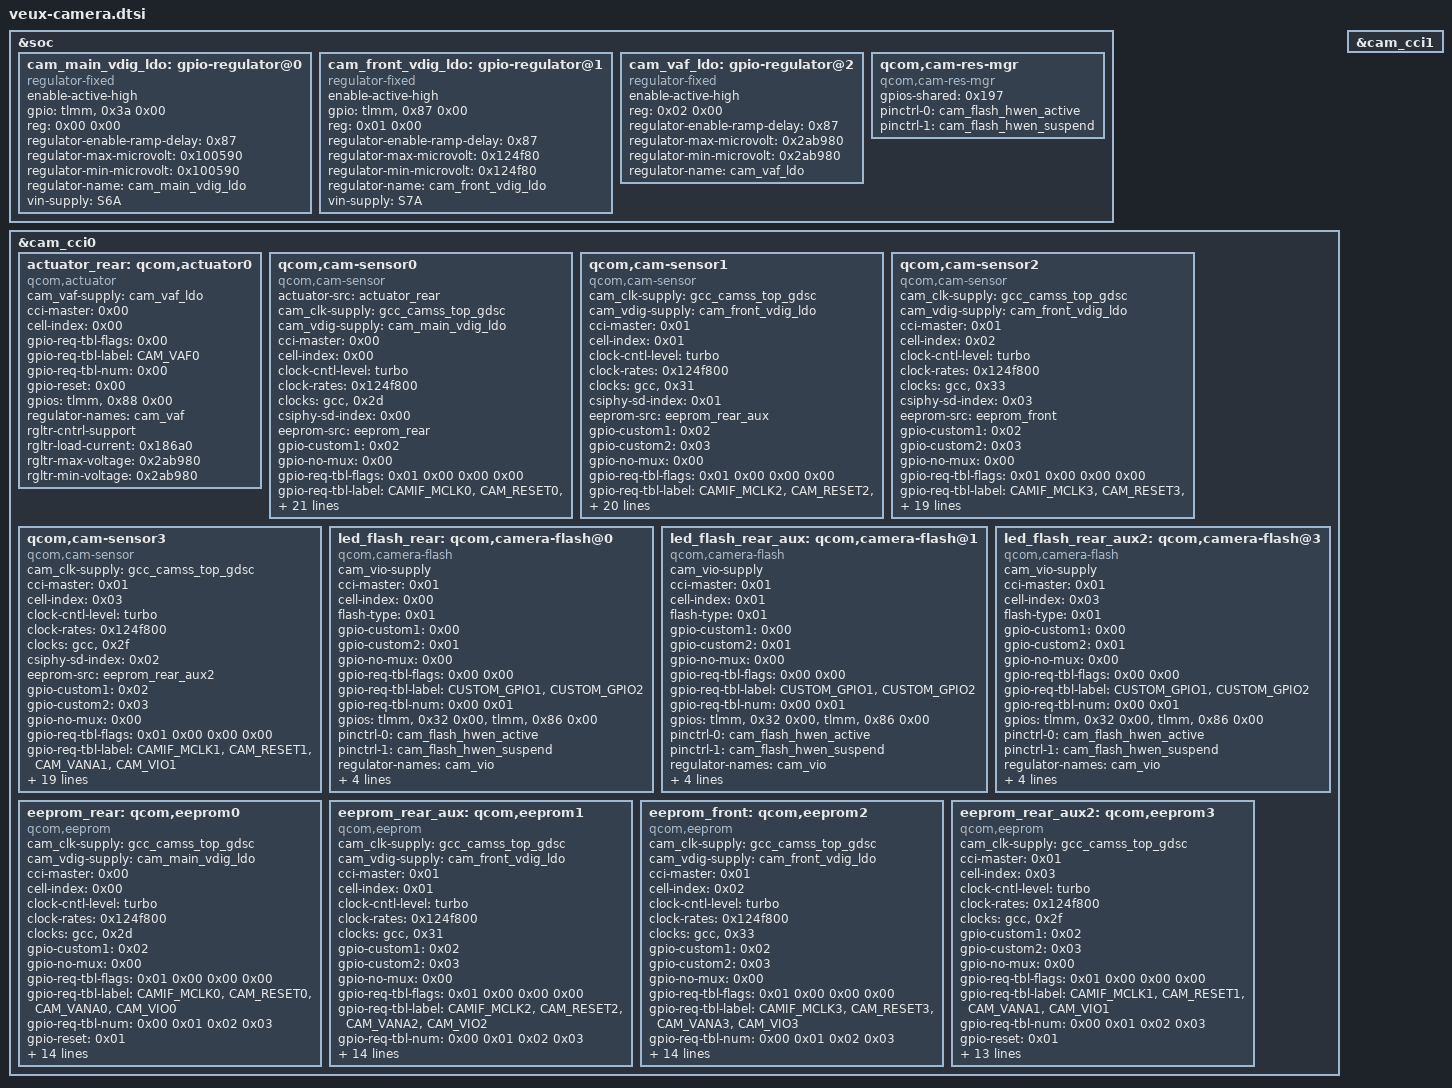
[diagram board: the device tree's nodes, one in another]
/* Xiaomi Poco X4 Pro 5G (veux) - Camera Subsystem */

/* Fragment 66 -> &soc */
&soc {

	/* Camera digital core voltage regulator for main image sensor */
cam_main_vdig_ldo: gpio-regulator@0 {
		compatible = "regulator-fixed";
		enable-active-high;
		gpio = <&tlmm>, <0x3a 0x00>;
		reg = <0x00 0x00>;
		regulator-enable-ramp-delay = <0x87>;
		regulator-max-microvolt = <0x100590>;
		regulator-min-microvolt = <0x100590>;
		regulator-name = "cam_main_vdig_ldo";
		vin-supply = <&S6A>;
	};

	cam_front_vdig_ldo: gpio-regulator@1 {
		compatible = "regulator-fixed";
		enable-active-high;
		gpio = <&tlmm>, <0x87 0x00>;
		reg = <0x01 0x00>;
		regulator-enable-ramp-delay = <0x87>;
		regulator-max-microvolt = <0x124f80>;
		regulator-min-microvolt = <0x124f80>;
		regulator-name = "cam_front_vdig_ldo";
		vin-supply = <&S7A>;
	};

	cam_vaf_ldo: gpio-regulator@2 {
		compatible = "regulator-fixed";
		enable-active-high;
		reg = <0x02 0x00>;
		regulator-enable-ramp-delay = <0x87>;
		regulator-max-microvolt = <0x2ab980>;
		regulator-min-microvolt = <0x2ab980>;
		regulator-name = "cam_vaf_ldo";
	};

	qcom,cam-res-mgr {
		compatible = "qcom,cam-res-mgr";
		gpios-shared = <0x197>;
		pinctrl-0 = <&cam_flash_hwen_active>;
		pinctrl-1 = <&cam_flash_hwen_suspend>;
		pinctrl-names = "cam_res_mgr_default", "cam_res_mgr_suspend";
		status = "ok";
	};
};

/* Fragment 67 -> &cam_cci0 */
/* Camera Control Interface 0 (CCI0): sensors, actuators, flash, EEPROM */
&cam_cci0 {

	/* Rear main camera autofocus actuator */
actuator_rear: qcom,actuator0 {
		cam_vaf-supply = <&cam_vaf_ldo>;
		cci-master = <0x00>;
		cell-index = <0x00>;
		compatible = "qcom,actuator";
		gpio-req-tbl-flags = <0x00>;
		gpio-req-tbl-label = "CAM_VAF0";
		gpio-req-tbl-num = <0x00>;
		gpio-reset = <0x00>;
		gpios = <&tlmm>, <0x88 0x00>;
		regulator-names = "cam_vaf";
		rgltr-cntrl-support;
		rgltr-load-current = <0x186a0>;
		rgltr-max-voltage = <0x2ab980>;
		rgltr-min-voltage = <0x2ab980>;
		status = "ok";
	};

	/* Primary rear camera sensor (108MP / 64MP) */
	qcom,cam-sensor0 {
		actuator-src = <&actuator_rear>;
		cam_clk-supply = <&gcc_camss_top_gdsc>;
		cam_vdig-supply = <&cam_main_vdig_ldo>;
		cci-master = <0x00>;
		cell-index = <0x00>;
		clock-cntl-level = "turbo";
		clock-names = "cam_clk";
		clock-rates = <0x124f800>;
		clocks = <&gcc>, <0x2d>;
		compatible = "qcom,cam-sensor";
		csiphy-sd-index = <0x00>;
		eeprom-src = <&eeprom_rear>;
		gpio-custom1 = <0x02>;
		gpio-no-mux = <0x00>;
		gpio-req-tbl-flags = <0x01 0x00 0x00 0x00>;
		gpio-req-tbl-label = "CAMIF_MCLK0", "CAM_RESET0", "CAM_VANA0", "CAM_VIO0";
		gpio-req-tbl-num = <0x00 0x01 0x02 0x03>;
		gpio-reset = <0x01>;
		gpio-standby = <0x03>;
		gpios = <&tlmm>, <0x1d 0x00>, <&tlmm>, <0x22 0x00>, <&tlmm>, <0x2b 0x00>, <&tlmm>, <0x5d 0x00>;
		led-flash-src = <&led_flash_rear>;
		pinctrl-0 = <&cam_sensor_mclk0_active>, <&cam_sensor_rear0_reset_active>;
		pinctrl-1 = <&cam_sensor_mclk0_suspend>, <&cam_sensor_rear0_reset_suspend>;
		pinctrl-names = "cam_default", "cam_suspend";
		pwm-switch;
		regulator-names = "cam_vdig", "cam_clk";
		rgltr-cntrl-support;
		rgltr-load-current = <0x100590 0x00>;
		rgltr-max-voltage = <0x100590 0x00>;
		rgltr-min-voltage = <0x100590 0x00>;
		sensor-mode = <0x00>;
		sensor-position-pitch = <0x00>;
		sensor-position-roll = <0x5a>;
		sensor-position-yaw = <0xb4>;
		status = "ok";
	};

	/* Ultra-wide rear camera sensor (8MP) */
	qcom,cam-sensor1 {
		cam_clk-supply = <&gcc_camss_top_gdsc>;
		cam_vdig-supply = <&cam_front_vdig_ldo>;
		cci-master = <0x01>;
		cell-index = <0x01>;
		clock-cntl-level = "turbo";
		clock-names = "cam_clk";
		clock-rates = <0x124f800>;
		clocks = <&gcc>, <0x31>;
		compatible = "qcom,cam-sensor";
		csiphy-sd-index = <0x01>;
		eeprom-src = <&eeprom_rear_aux>;
		gpio-custom1 = <0x02>;
		gpio-custom2 = <0x03>;
		gpio-no-mux = <0x00>;
		gpio-req-tbl-flags = <0x01 0x00 0x00 0x00>;
		gpio-req-tbl-label = "CAMIF_MCLK2", "CAM_RESET2", "CAM_VANA2", "CAM_VIO2";
		gpio-req-tbl-num = <0x00 0x01 0x02 0x03>;
		gpio-reset = <0x01>;
		gpios = <&tlmm>, <0x1f 0x00>, <&tlmm>, <0x24 0x00>, <&tlmm>, <0x85 0x00>, <&tlmm>, <0x86 0x00>;
		led-flash-src = <&led_flash_rear_aux>;
		pinctrl-0 = <&cam_sensor_mclk2_active>, <&cam_sensor_rear2_reset_active>;
		pinctrl-1 = <&cam_sensor_mclk2_suspend>, <&cam_sensor_rear2_reset_suspend>;
		pinctrl-names = "cam_default", "cam_suspend";
		pwm-switch;
		regulator-names = "cam_vdig", "cam_clk";
		rgltr-cntrl-support;
		rgltr-load-current = <0x124f80 0x00>;
		rgltr-max-voltage = <0x124f80 0x00>;
		rgltr-min-voltage = <0x124f80 0x00>;
		sensor-mode = <0x00>;
		sensor-position-pitch = <0x00>;
		sensor-position-roll = <0x5a>;
		sensor-position-yaw = <0xb4>;
		status = "ok";
	};

	/* Front selfie camera sensor (16MP) */
	qcom,cam-sensor2 {
		cam_clk-supply = <&gcc_camss_top_gdsc>;
		cam_vdig-supply = <&cam_front_vdig_ldo>;
		cci-master = <0x01>;
		cell-index = <0x02>;
		clock-cntl-level = "turbo";
		clock-names = "cam_clk";
		clock-rates = <0x124f800>;
		clocks = <&gcc>, <0x33>;
		compatible = "qcom,cam-sensor";
		csiphy-sd-index = <0x03>;
		eeprom-src = <&eeprom_front>;
		gpio-custom1 = <0x02>;
		gpio-custom2 = <0x03>;
		gpio-no-mux = <0x00>;
		gpio-req-tbl-flags = <0x01 0x00 0x00 0x00>;
		gpio-req-tbl-label = "CAMIF_MCLK3", "CAM_RESET3", "CAM_VANA3", "CAM_VIO3";
		gpio-req-tbl-num = <0x00 0x01 0x02 0x03>;
		gpio-reset = <0x01>;
		gpios = <&tlmm>, <0x20 0x00>, <&tlmm>, <0x25 0x00>, <&tlmm>, <0x85 0x00>, <&tlmm>, <0x86 0x00>;
		pinctrl-0 = <&cam_sensor_mclk3_active>, <&cam_sensor_front0_reset_active>;
		pinctrl-1 = <&cam_sensor_mclk3_suspend>, <&cam_sensor_front0_reset_suspend>;
		pinctrl-names = "cam_default", "cam_suspend";
		pwm-switch;
		regulator-names = "cam_vdig", "cam_clk";
		rgltr-cntrl-support;
		rgltr-load-current = <0x1d4c0 0x00>;
		rgltr-max-voltage = <0x124f80 0x00>;
		rgltr-min-voltage = <0x124f80 0x00>;
		sensor-mode = <0x00>;
		sensor-position-pitch = <0x00>;
		sensor-position-roll = <0x10e>;
		sensor-position-yaw = <0x00>;
		status = "ok";
	};

	/* Macro rear camera sensor (2MP) */
	qcom,cam-sensor3 {
		cam_clk-supply = <&gcc_camss_top_gdsc>;
		cci-master = <0x01>;
		cell-index = <0x03>;
		clock-cntl-level = "turbo";
		clock-names = "cam_clk";
		clock-rates = <0x124f800>;
		clocks = <&gcc>, <0x2f>;
		compatible = "qcom,cam-sensor";
		csiphy-sd-index = <0x02>;
		eeprom-src = <&eeprom_rear_aux2>;
		gpio-custom1 = <0x02>;
		gpio-custom2 = <0x03>;
		gpio-no-mux = <0x00>;
		gpio-req-tbl-flags = <0x01 0x00 0x00 0x00>;
		gpio-req-tbl-label = "CAMIF_MCLK1", "CAM_RESET1", "CAM_VANA1", "CAM_VIO1";
		gpio-req-tbl-num = <0x00 0x01 0x02 0x03>;
		gpio-reset = <0x01>;
		gpios = <&tlmm>, <0x1e 0x00>, <&tlmm>, <0x23 0x00>, <&tlmm>, <0x85 0x00>, <&tlmm>, <0x86 0x00>;
		led-flash-src = <&led_flash_rear_aux2>;
		pinctrl-0 = <&cam_sensor_mclk1_active>, <&cam_sensor_rear1_reset_active>;
		pinctrl-1 = <&cam_sensor_mclk1_suspend>, <&cam_sensor_rear1_reset_suspend>;
		pinctrl-names = "cam_default", "cam_suspend";
		pwm-switch;
		regulator-names = "cam_clk";
		rgltr-cntrl-support;
		rgltr-load-current = <0x00>;
		rgltr-max-voltage = <0x00>;
		rgltr-min-voltage = <0x00>;
		sensor-mode = <0x00>;
		sensor-position-pitch = <0x00>;
		sensor-position-roll = <0x5a>;
		sensor-position-yaw = <0xb4>;
		status = "ok";
	};

	led_flash_rear: qcom,camera-flash@0 {
		cam_vio-supply;
		cci-master = <0x01>;
		cell-index = <0x00>;
		compatible = "qcom,camera-flash";
		flash-type = <0x01>;
		gpio-custom1 = <0x00>;
		gpio-custom2 = <0x01>;
		gpio-no-mux = <0x00>;
		gpio-req-tbl-flags = <0x00 0x00>;
		gpio-req-tbl-label = "CUSTOM_GPIO1", "CUSTOM_GPIO2";
		gpio-req-tbl-num = <0x00 0x01>;
		gpios = <&tlmm>, <0x32 0x00>, <&tlmm>, <0x86 0x00>;
		pinctrl-0 = <&cam_flash_hwen_active>;
		pinctrl-1 = <&cam_flash_hwen_suspend>;
		pinctrl-names = "cam_default", "cam_suspend";
		regulator-names = "cam_vio";
		rgltr-cntrl-support;
		rgltr-load-current = <0x1d4c0>;
		rgltr-max-voltage = <0x1b7740>;
		rgltr-min-voltage = <0x1b7740>;
		status = "ok";
	};

	led_flash_rear_aux: qcom,camera-flash@1 {
		cam_vio-supply;
		cci-master = <0x01>;
		cell-index = <0x01>;
		compatible = "qcom,camera-flash";
		flash-type = <0x01>;
		gpio-custom1 = <0x00>;
		gpio-custom2 = <0x01>;
		gpio-no-mux = <0x00>;
		gpio-req-tbl-flags = <0x00 0x00>;
		gpio-req-tbl-label = "CUSTOM_GPIO1", "CUSTOM_GPIO2";
		gpio-req-tbl-num = <0x00 0x01>;
		gpios = <&tlmm>, <0x32 0x00>, <&tlmm>, <0x86 0x00>;
		pinctrl-0 = <&cam_flash_hwen_active>;
		pinctrl-1 = <&cam_flash_hwen_suspend>;
		pinctrl-names = "cam_default", "cam_suspend";
		regulator-names = "cam_vio";
		rgltr-cntrl-support;
		rgltr-load-current = <0x1d4c0>;
		rgltr-max-voltage = <0x1b7740>;
		rgltr-min-voltage = <0x1b7740>;
		status = "ok";
	};

	led_flash_rear_aux2: qcom,camera-flash@3 {
		cam_vio-supply;
		cci-master = <0x01>;
		cell-index = <0x03>;
		compatible = "qcom,camera-flash";
		flash-type = <0x01>;
		gpio-custom1 = <0x00>;
		gpio-custom2 = <0x01>;
		gpio-no-mux = <0x00>;
		gpio-req-tbl-flags = <0x00 0x00>;
		gpio-req-tbl-label = "CUSTOM_GPIO1", "CUSTOM_GPIO2";
		gpio-req-tbl-num = <0x00 0x01>;
		gpios = <&tlmm>, <0x32 0x00>, <&tlmm>, <0x86 0x00>;
		pinctrl-0 = <&cam_flash_hwen_active>;
		pinctrl-1 = <&cam_flash_hwen_suspend>;
		pinctrl-names = "cam_default", "cam_suspend";
		regulator-names = "cam_vio";
		rgltr-cntrl-support;
		rgltr-load-current = <0x1d4c0>;
		rgltr-max-voltage = <0x1b7740>;
		rgltr-min-voltage = <0x1b7740>;
		status = "ok";
	};

	eeprom_rear: qcom,eeprom0 {
		cam_clk-supply = <&gcc_camss_top_gdsc>;
		cam_vdig-supply = <&cam_main_vdig_ldo>;
		cci-master = <0x00>;
		cell-index = <0x00>;
		clock-cntl-level = "turbo";
		clock-names = "cam_clk";
		clock-rates = <0x124f800>;
		clocks = <&gcc>, <0x2d>;
		compatible = "qcom,eeprom";
		gpio-custom1 = <0x02>;
		gpio-no-mux = <0x00>;
		gpio-req-tbl-flags = <0x01 0x00 0x00 0x00>;
		gpio-req-tbl-label = "CAMIF_MCLK0", "CAM_RESET0", "CAM_VANA0", "CAM_VIO0";
		gpio-req-tbl-num = <0x00 0x01 0x02 0x03>;
		gpio-reset = <0x01>;
		gpio-standby = <0x03>;
		gpios = <&tlmm>, <0x1d 0x00>, <&tlmm>, <0x22 0x00>, <&tlmm>, <0x2b 0x00>, <&tlmm>, <0x5d 0x00>;
		pinctrl-0 = <&cam_sensor_mclk0_active>, <&cam_sensor_rear0_reset_active>;
		pinctrl-1 = <&cam_sensor_mclk0_suspend>, <&cam_sensor_rear0_reset_suspend>;
		pinctrl-names = "cam_default", "cam_suspend";
		pwm-switch;
		regulator-names = "cam_vdig", "cam_clk";
		rgltr-cntrl-support;
		rgltr-load-current = <0x100590 0x00>;
		rgltr-max-voltage = <0x100590 0x00>;
		rgltr-min-voltage = <0x100590 0x00>;
		sensor-mode = <0x00>;
		status = "ok";
	};

	eeprom_rear_aux: qcom,eeprom1 {
		cam_clk-supply = <&gcc_camss_top_gdsc>;
		cam_vdig-supply = <&cam_front_vdig_ldo>;
		cci-master = <0x01>;
		cell-index = <0x01>;
		clock-cntl-level = "turbo";
		clock-names = "cam_clk";
		clock-rates = <0x124f800>;
		clocks = <&gcc>, <0x31>;
		compatible = "qcom,eeprom";
		gpio-custom1 = <0x02>;
		gpio-custom2 = <0x03>;
		gpio-no-mux = <0x00>;
		gpio-req-tbl-flags = <0x01 0x00 0x00 0x00>;
		gpio-req-tbl-label = "CAMIF_MCLK2", "CAM_RESET2", "CAM_VANA2", "CAM_VIO2";
		gpio-req-tbl-num = <0x00 0x01 0x02 0x03>;
		gpio-reset = <0x01>;
		gpios = <&tlmm>, <0x1f 0x00>, <&tlmm>, <0x24 0x00>, <&tlmm>, <0x85 0x00>, <&tlmm>, <0x86 0x00>;
		pinctrl-0 = <&cam_sensor_mclk2_active>, <&cam_sensor_rear2_reset_active>;
		pinctrl-1 = <&cam_sensor_mclk2_suspend>, <&cam_sensor_rear2_reset_suspend>;
		pinctrl-names = "cam_default", "cam_suspend";
		pwm-switch;
		regulator-names = "cam_vdig", "cam_clk";
		rgltr-cntrl-support;
		rgltr-load-current = <0x124f80 0x00>;
		rgltr-max-voltage = <0x124f80 0x00>;
		rgltr-min-voltage = <0x124f80 0x00>;
		sensor-mode = <0x00>;
		status = "ok";
	};

	eeprom_front: qcom,eeprom2 {
		cam_clk-supply = <&gcc_camss_top_gdsc>;
		cam_vdig-supply = <&cam_front_vdig_ldo>;
		cci-master = <0x01>;
		cell-index = <0x02>;
		clock-cntl-level = "turbo";
		clock-names = "cam_clk";
		clock-rates = <0x124f800>;
		clocks = <&gcc>, <0x33>;
		compatible = "qcom,eeprom";
		gpio-custom1 = <0x02>;
		gpio-custom2 = <0x03>;
		gpio-no-mux = <0x00>;
		gpio-req-tbl-flags = <0x01 0x00 0x00 0x00>;
		gpio-req-tbl-label = "CAMIF_MCLK3", "CAM_RESET3", "CAM_VANA3", "CAM_VIO3";
		gpio-req-tbl-num = <0x00 0x01 0x02 0x03>;
		gpio-reset = <0x01>;
		gpios = <&tlmm>, <0x20 0x00>, <&tlmm>, <0x25 0x00>, <&tlmm>, <0x85 0x00>, <&tlmm>, <0x86 0x00>;
		pinctrl-0 = <&cam_sensor_mclk3_active>, <&cam_sensor_front0_reset_active>;
		pinctrl-1 = <&cam_sensor_mclk3_suspend>, <&cam_sensor_front0_reset_suspend>;
		pinctrl-names = "cam_default", "cam_suspend";
		pwm-switch;
		regulator-names = "cam_vdig", "cam_clk";
		rgltr-cntrl-support;
		rgltr-load-current = <0x1d4c0 0x00>;
		rgltr-max-voltage = <0x124f80 0x00>;
		rgltr-min-voltage = <0x124f80 0x00>;
		sensor-mode = <0x00>;
		status = "ok";
	};

	eeprom_rear_aux2: qcom,eeprom3 {
		cam_clk-supply = <&gcc_camss_top_gdsc>;
		cci-master = <0x01>;
		cell-index = <0x03>;
		clock-cntl-level = "turbo";
		clock-names = "cam_clk";
		clock-rates = <0x124f800>;
		clocks = <&gcc>, <0x2f>;
		compatible = "qcom,eeprom";
		gpio-custom1 = <0x02>;
		gpio-custom2 = <0x03>;
		gpio-no-mux = <0x00>;
		gpio-req-tbl-flags = <0x01 0x00 0x00 0x00>;
		gpio-req-tbl-label = "CAMIF_MCLK1", "CAM_RESET1", "CAM_VANA1", "CAM_VIO1";
		gpio-req-tbl-num = <0x00 0x01 0x02 0x03>;
		gpio-reset = <0x01>;
		gpios = <&tlmm>, <0x1e 0x00>, <&tlmm>, <0x23 0x00>, <&tlmm>, <0x85 0x00>, <&tlmm>, <0x86 0x00>;
		pinctrl-0 = <&cam_sensor_mclk1_active>, <&cam_sensor_rear1_reset_active>;
		pinctrl-1 = <&cam_sensor_mclk1_suspend>, <&cam_sensor_rear1_reset_suspend>;
		pinctrl-names = "cam_default", "cam_suspend";
		pwm-switch;
		regulator-names = "cam_clk";
		rgltr-cntrl-support;
		rgltr-load-current = <0x00>;
		rgltr-max-voltage = <0x00>;
		rgltr-min-voltage = <0x00>;
		sensor-mode = <0x00>;
		status = "ok";
	};
};

/* Fragment 68 -> &cam_cci1 */
&cam_cci1 {

};
